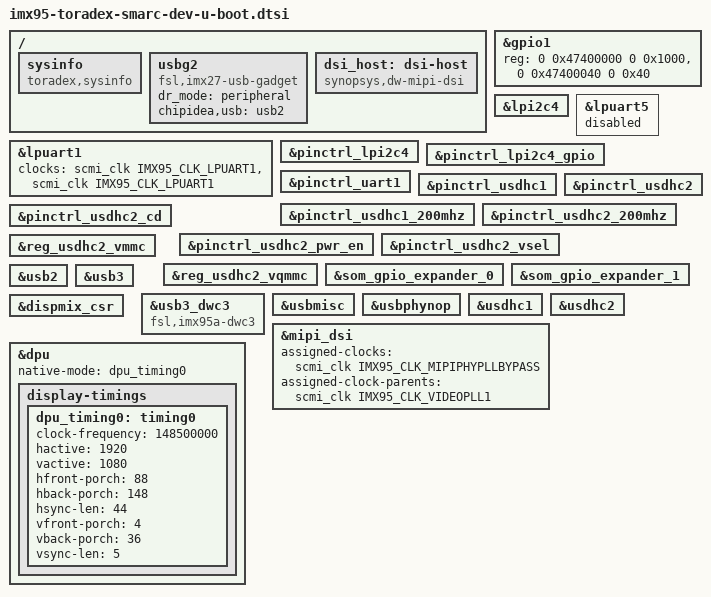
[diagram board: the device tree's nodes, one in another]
// SPDX-License-Identifier: GPL-2.0-or-later OR MIT
/* Copyright (C) 2025 Toradex */

#include "imx95-u-boot.dtsi"

/ {
	sysinfo {
		compatible = "toradex,sysinfo";
	};

	usbg2 {
		compatible = "fsl,imx27-usb-gadget";
		dr_mode = "peripheral";
		chipidea,usb = <&usb2>;
		bootph-pre-ram;
	};

	dsi_host: dsi-host {
		compatible = "synopsys,dw-mipi-dsi";
		status = "okay";
	};
};

&gpio1 {
	reg = <0 0x47400000 0 0x1000>, <0 0x47400040 0 0x40>;
	bootph-pre-ram;
};

&lpi2c4 {
	bootph-pre-ram;
};

&lpuart1 {
	clocks = <&scmi_clk IMX95_CLK_LPUART1>, <&scmi_clk IMX95_CLK_LPUART1>;
	clock-names = "ipg", "per";
	bootph-pre-ram;
};

/* Conflict with JTAG interface */
&lpuart5 {
	status = "disabled";
};

&pinctrl_lpi2c4 {
	bootph-pre-ram;
};

&pinctrl_lpi2c4_gpio {
	bootph-pre-ram;
};

&pinctrl_uart1 {
	bootph-pre-ram;
};

&pinctrl_usdhc1 {
	bootph-pre-ram;
};

&pinctrl_usdhc1_200mhz {
	bootph-pre-ram;
};

&pinctrl_usdhc2 {
	bootph-pre-ram;
};

&pinctrl_usdhc2_200mhz {
	bootph-pre-ram;
};

&pinctrl_usdhc2_cd {
	bootph-pre-ram;
};

&pinctrl_usdhc2_pwr_en {
	bootph-pre-ram;
};

&pinctrl_usdhc2_vsel {
	bootph-pre-ram;
};

&reg_usdhc2_vmmc {
	bootph-pre-ram;
};

&reg_usdhc2_vqmmc {
	bootph-pre-ram;
};

&som_gpio_expander_0 {
	bootph-pre-ram;
};

&som_gpio_expander_1 {
	bootph-pre-ram;
};

&usb2 {
	bootph-pre-ram;
	/delete-property/power-domains;
};

&usb3 {
	/delete-property/power-domains;
};

&usb3_dwc3 {
	compatible = "fsl,imx95a-dwc3", "fsl,imx8mq-dwc3", "snps,dwc3";
};

&usbmisc {
	bootph-pre-ram;
};

&usbphynop {
	bootph-pre-ram;
};

&usdhc1 {
	bootph-pre-ram;
};

&usdhc2 {
	bootph-pre-ram;
};

&dispmix_csr {
	/delete-property/ assigned-clocks;
	/delete-property/ assigned-clock-rates;
	/delete-property/ assigned-clock-parents;
};

&mipi_dsi {
	assigned-clocks = <&scmi_clk IMX95_CLK_MIPIPHYPLLBYPASS>;
	assigned-clock-parents = <&scmi_clk IMX95_CLK_VIDEOPLL1>;
};

&dpu {
	native-mode = <&dpu_timing0>;
	display-timings {
		dpu_timing0: timing0 {
			clock-frequency = <148500000>;
			hactive = <1920>;
			vactive = <1080>;
			hfront-porch = <88>;
			hback-porch = <148>;
			hsync-len = <44>;
			vfront-porch = <4>;
			vback-porch = <36>;
			vsync-len = <5>;
		};
	};
};
